AUTOSAR XML (schema 4-0-3)
standard types defined: uint8, Boolean
package /AUTOSAR_Platform/DataConstrs
  range DC_Boolean: raw 0..1
package /DataTypes/Units
  unit NoUnit1: display-name=NoUnit, factor-si-to-unit=1, offset-si-to-unit=0
package /PATAC/MSM/ComponentTypes
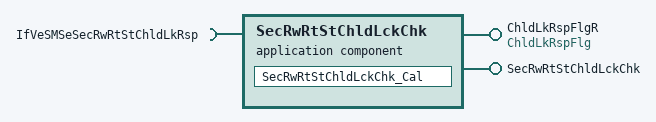
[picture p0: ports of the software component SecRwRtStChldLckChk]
  application sw component type SecRwRtStChldLckChk
    provide port ChldLkRspFlgR: nonqueued-sender-com-spec{data-element=ChldLkRspFlg/Val, init-value=0}, provided-interface=ChldLkRspFlg
    provide port SecRwRtStChldLckChk: server-com-spec{operation=Cal, queue-length=1}, provided-interface=SecRwRtStChldLckChk
    require port IfVeSMSeSecRwRtStChldLkRsp: nonqueued-receiver-com-spec{data-element=IfVeSMSeSecRwRtStChldLkRsp/Val, filter=data-filter-type=ALWAYS, init-value=0}, required-interface=IfVeSMSeSecRwRtStChldLkRsp
    behavior SecRwRtStChldLckChk_InternalBehavior
      operation invoked event OIT_SecRwRtStChldLckChk_Cal_SecRwRtStChldLckChk_Cal: start-on-event=SecRwRtStChldLckChk_Cal, operation=SecRwRtStChldLckChk.Cal
      runnable SecRwRtStChldLckChk_Cal
        data-receive-point-by-arguments:
          access REC_IfVeSMSeSecRwRtStChldLkRsp_Val: accessed-variable=IfVeSMSeSecRwRtStChldLkRsp.Val
        data-send-points:
          access SEND_ChldLkRspFlgR_Val: accessed-variable=ChldLkRspFlgR.Val
  swc implementation SecRwRtStChldLckChk_Implementation: behavior=SecRwRtStChldLckChk_InternalBehavior
    code-descriptors:
      code Default: artifact-descriptors=autosar-engineering-object={short-label=Default, category=SWSRC}
package /PATAC/MSM/DataTypes
  impl type SeatChldLkSt: category=VALUE, base-type=uint8, compu {0=ChldLkSt_NoActive, 1=ChldLkSt_Lock, 2=ChldLkSt_Unlock}
package /PATAC/MSM/ModeAdjust/Interfaces
  sender receiver interface IfVeSMSeSecRwRtStChldLkRsp: invalidation-policy{data-element=IfVeSMSeSecRwRtStChldLkRsp/Val, handle-invalid=DONT-INVALIDATE}
    data Val: type=SeatChldLkSt
package /PATAC/MSM/ModeAdjust/PortInterface
  client server interface SecRwRtStChldLckChk
    operation Cal
  sender receiver interface ChldLkRspFlg: invalidation-policy{data-element=ChldLkRspFlg/Val, handle-invalid=DONT-INVALIDATE}
    data Val: type=Boolean
